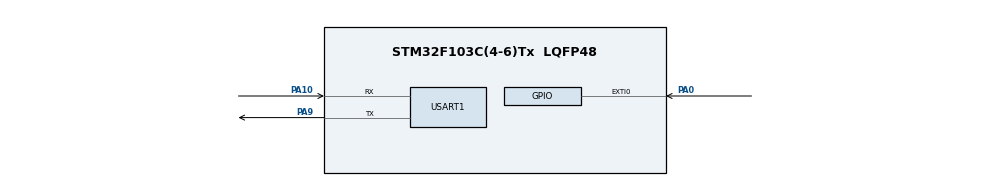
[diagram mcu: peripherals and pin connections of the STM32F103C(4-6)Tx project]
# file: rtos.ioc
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FREERTOS.INCLUDE_vTaskDelayUntil=1
FREERTOS.Tasks01=defaultTask,0,128,StartDefaultTask,Default,NULL,Dynamic,NULL,NULL
FREERTOS.configUSE_TIMERS=1
Mcu.Family=STM32F1
Mcu.Name=STM32F103C(4-6)Tx
Mcu.Package=LQFP48
NVIC.EXTI0_IRQn=true\:5\:0\:false\:false\:true\:true\:true\:true\:true
NVIC.PriorityGroup=NVIC_PRIORITYGROUP_4
PA0-WKUP.GPIO_PuPd=GPIO_PULLUP
PA0-WKUP.Signal=GPXTI0
PA10.Mode=Asynchronous
PA10.Signal=USART1_RX
PA13.Mode=Serial_Wire
PA13.Signal=SYS_JTMS-SWDIO
PA14.Mode=Serial_Wire
PA14.Signal=SYS_JTCK-SWCLK
PA9.Mode=Asynchronous
PA9.Signal=USART1_TX
ProjectManager.HeapSize=0x200
ProjectManager.StackSize=0x400
ProjectManager.TargetToolchain=STM32CubeIDE
RCC.APB1Freq_Value=8000000
RCC.APB2Freq_Value=8000000
USART1.VirtualMode=VM_ASYNC
VP_FREERTOS_VS_CMSIS_V1.Mode=CMSIS_V1
board=custom

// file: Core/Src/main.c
/* USER CODE BEGIN Header */
/**
  ******************************************************************************
  * @file           : main.c
  * @brief          : Main program body
  ******************************************************************************
  * @attention
  *
  * Copyright (c) 2025 STMicroelectronics.
  * All rights reserved.
  *
  * This software is licensed under terms that can be found in the LICENSE file
  * in the root directory of this software component.
  * If no LICENSE file comes with this software, it is provided AS-IS.
  *
  ******************************************************************************
  */
/* USER CODE END Header */
#include "main.h"
#include "cmsis_os.h"

/* USER CODE BEGIN Includes */
#include <string.h>
#include <stdio.h>
/* USER CODE END Includes */

UART_HandleTypeDef huart1;

osThreadId defaultTaskHandle;
/* USER CODE BEGIN PV */
typedef enum {
  SRC_COUNTER = 0,
  SRC_SHARED  = 1
} DataSource_t;

typedef struct {
  DataSource_t source;
  uint16_t value;
} UARTData_t;

volatile uint8_t counter = 0;
static uint16_t shared = 100;

SemaphoreHandle_t xButtonSemaphore;
QueueHandle_t xUARTDataQueue;
SemaphoreHandle_t xSharedMutex;
/* USER CODE END PV */

void SystemClock_Config(void);
static void MX_GPIO_Init(void);
static void MX_USART1_UART_Init(void);
void StartDefaultTask(void const * argument);

/* USER CODE BEGIN 0 */
void HAL_GPIO_EXTI_Callback(uint16_t GPIO_Pin)
{
    BaseType_t xHigherPriorityTaskWoken = pdFALSE;
    if (GPIO_Pin == GPIO_PIN_0) /* PA0 */
    {
        counter++;
        if (counter >= 9U) counter = 0U;

        /* Give semaphore from ISR */
        if (xButtonSemaphore != NULL)
        {
            xSemaphoreGiveFromISR(xButtonSemaphore, &xHigherPriorityTaskWoken);
            portYIELD_FROM_ISR(xHigherPriorityTaskWoken);
        }
    }
}

/* USER CODE END 0 */

int main(void)
{

  /* MCU Configuration--------------------------------------------------------*/

  /* Reset of all peripherals, Initializes the Flash interface and the Systick. */
  HAL_Init();

  /* Configure the system clock */
  SystemClock_Config();

  /* Initialize all configured peripherals */
  MX_GPIO_Init();
  MX_USART1_UART_Init();
  /* USER CODE BEGIN 2 */
  void CalcSwitch1_Task(void *pvParameters);
  void IncreaseVar_Task(void *pvParameters);
  void DecreaseVar_Task(void *pvParameters);
  void UART_Task(void *pvParameters);

  xSharedMutex = xSemaphoreCreateMutex();
  xUARTDataQueue = xQueueCreate(10, sizeof(UARTData_t));
  xButtonSemaphore = xSemaphoreCreateBinary();

  xTaskCreate(CalcSwitch1_Task, "CalcSwitch1", 128, NULL, 1, NULL);
  xTaskCreate(IncreaseVar_Task, "IncreaseVar", 128, NULL, 1, NULL);
  xTaskCreate(DecreaseVar_Task, "DecreaseVar", 128, NULL, 1, NULL);
  xTaskCreate(UART_Task, "UARTTask", 128, NULL, 1, NULL);
  /* USER CODE END 2 */

  /* Create the thread(s) */
  /* definition and creation of defaultTask */
  osThreadDef(defaultTask, StartDefaultTask, osPriorityNormal, 0, 128);
  defaultTaskHandle = osThreadCreate(osThread(defaultTask), NULL);

  /* Start scheduler */
  osKernelStart();

  /* We should never get here as control is now taken by the scheduler */

  /* Infinite loop */
  while (1)
  {

  }
}

void SystemClock_Config(void)
{
  RCC_OscInitTypeDef RCC_OscInitStruct = {0};
  RCC_ClkInitTypeDef RCC_ClkInitStruct = {0};

  /** Initializes the RCC Oscillators according to the specified parameters
  * in the RCC_OscInitTypeDef structure.
  */
  RCC_OscInitStruct.OscillatorType = RCC_OSCILLATORTYPE_HSI;
  RCC_OscInitStruct.HSIState = RCC_HSI_ON;
  RCC_OscInitStruct.HSICalibrationValue = RCC_HSICALIBRATION_DEFAULT;
  RCC_OscInitStruct.PLL.PLLState = RCC_PLL_NONE;
  if (HAL_RCC_OscConfig(&RCC_OscInitStruct) != HAL_OK)
  {
    Error_Handler();
  }

  /** Initializes the CPU, AHB and APB buses clocks
  */
  RCC_ClkInitStruct.ClockType = RCC_CLOCKTYPE_HCLK|RCC_CLOCKTYPE_SYSCLK
                              |RCC_CLOCKTYPE_PCLK1|RCC_CLOCKTYPE_PCLK2;
  RCC_ClkInitStruct.SYSCLKSource = RCC_SYSCLKSOURCE_HSI;
  RCC_ClkInitStruct.AHBCLKDivider = RCC_SYSCLK_DIV1;
  RCC_ClkInitStruct.APB1CLKDivider = RCC_HCLK_DIV1;
  RCC_ClkInitStruct.APB2CLKDivider = RCC_HCLK_DIV1;

  if (HAL_RCC_ClockConfig(&RCC_ClkInitStruct, FLASH_LATENCY_0) != HAL_OK)
  {
    Error_Handler();
  }
}

static void MX_USART1_UART_Init(void)
{

  huart1.Instance = USART1;
  huart1.Init.BaudRate = 115200;
  huart1.Init.WordLength = UART_WORDLENGTH_8B;
  huart1.Init.StopBits = UART_STOPBITS_1;
  huart1.Init.Parity = UART_PARITY_NONE;
  huart1.Init.Mode = UART_MODE_TX_RX;
  huart1.Init.HwFlowCtl = UART_HWCONTROL_NONE;
  huart1.Init.OverSampling = UART_OVERSAMPLING_16;
  if (HAL_UART_Init(&huart1) != HAL_OK)
  {
    Error_Handler();
  }

}

static void MX_GPIO_Init(void)
{
  GPIO_InitTypeDef GPIO_InitStruct = {0};

  /* GPIO Ports Clock Enable */
  __HAL_RCC_GPIOA_CLK_ENABLE();

  /*Configure GPIO pin : PA0 */
  GPIO_InitStruct.Pin = GPIO_PIN_0;
  GPIO_InitStruct.Mode = GPIO_MODE_IT_RISING;
  GPIO_InitStruct.Pull = GPIO_PULLUP;
  HAL_GPIO_Init(GPIOA, &GPIO_InitStruct);

  /* EXTI interrupt init*/
  HAL_NVIC_SetPriority(EXTI0_IRQn, 5, 0);
  HAL_NVIC_EnableIRQ(EXTI0_IRQn);

}

/* USER CODE BEGIN 4 */
	void CalcSwitch1_Task(void *pvParameters)
{
    (void)pvParameters;
    const TickType_t waitTicks = 2;
    UARTData_t msg;
    while(1)
    {
        if (xSemaphoreTake(xButtonSemaphore, waitTicks) == pdTRUE)
        {
            uint8_t local_cnt;
            local_cnt = counter;
            msg.source = SRC_COUNTER;
            msg.value = (uint16_t)local_cnt * 10U;
            xQueueSend(xUARTDataQueue, &msg, pdMS_TO_TICKS(10));
        }
    }
}

	void IncreaseVar_Task(void *pvParameters)
	  {
	      (void)pvParameters;
	      const TickType_t period = 10; /* 10 ms */
	      TickType_t lastWake = xTaskGetTickCount();
	      UARTData_t msg;
	      while(1)
	      {
	          vTaskDelayUntil(&lastWake, period);
	          if (xSemaphoreTake(xSharedMutex, pdMS_TO_TICKS(5)) == pdTRUE)
	          {
	              shared++;
	              if (shared > 200U) shared = 100U;
	              msg.source = SRC_SHARED;
	              msg.value = shared;
	              xSemaphoreGive(xSharedMutex);
	              xQueueSend(xUARTDataQueue, &msg, pdMS_TO_TICKS(10));
	          }
	      }
	  }

	  void DecreaseVar_Task(void *pvParameters)
	  {
	      (void)pvParameters;
	      const TickType_t period = 12; /* 12 ms */
	      TickType_t lastWake = xTaskGetTickCount();
	      UARTData_t msg;
	      while(1)
	      {
	          vTaskDelayUntil(&lastWake, period);
	          if (xSemaphoreTake(xSharedMutex, pdMS_TO_TICKS(5)) == pdTRUE)
	          {
	        	  shared--;
	        	  if (shared < 100U) shared = 200U;
	              msg.source = SRC_SHARED;
	              msg.value = shared;
	              xSemaphoreGive(xSharedMutex);
	              xQueueSend(xUARTDataQueue, &msg, pdMS_TO_TICKS(10));
	          }
	      }
	  }

	  void UART_Task(void *pvParameters)
	  {
	      (void)pvParameters;
	      const TickType_t period = 5; /* 5 ms */
	      TickType_t lastWake = xTaskGetTickCount();
	      UARTData_t recv;
	      char outbuf[64];
	      while(1)
	      {
	          vTaskDelayUntil(&lastWake, period);
	          while (xQueueReceive(xUARTDataQueue, &recv, 0) == pdPASS)
	          {
	              if (recv.source == SRC_SHARED)
	                  snprintf(outbuf, sizeof(outbuf), "shared: %u\r\n", (unsigned)recv.value);
	              else
	                  snprintf(outbuf, sizeof(outbuf), "counterx10: %u\r\n", (unsigned)recv.value);
	              HAL_UART_Transmit(&huart1, (uint8_t*)outbuf, strlen(outbuf), HAL_MAX_DELAY);
	          }
	      }
	  }

/* USER CODE END 4 */

void StartDefaultTask(void const * argument)
{
  for(;;)
  {
    osDelay(1);
  }
}

void Error_Handler(void)
{
  __disable_irq();
  while (1)
  {
  }
}
